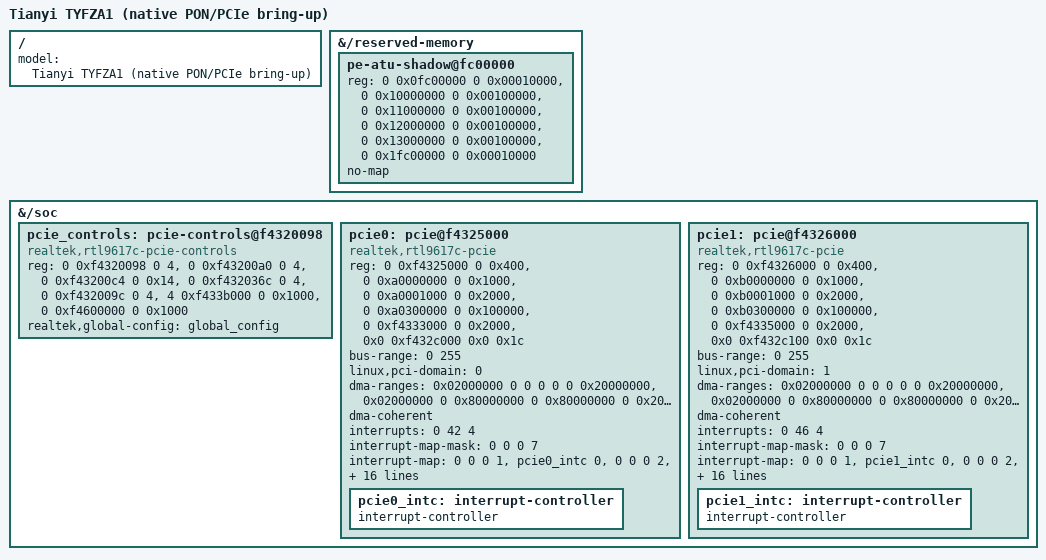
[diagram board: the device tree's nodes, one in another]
// SerDes data:stock DTB SHA256 5124f860df3bcd2e20b87d058e19b1ddfdc7a46c9d876663ba9feeff5a0f13ac.
// SPDX-License-Identifier: GPL-2.0-only
#include "rtl9617c-tyfza1-pon-status.dts"

/ { model = "Tianyi TYFZA1 (native PON/PCIe bring-up)"; };

&{/reserved-memory} {
 /* PE ATU shadows these RAM addresses with code or MMIO. Keep skb and
  * DMA allocations out of every window installed by pe_probe_core_start(). */
 pe-atu-shadow@fc00000 {
  reg = <0 0x0fc00000 0 0x00010000>,
        <0 0x10000000 0 0x00100000>,
        <0 0x11000000 0 0x00100000>,
        <0 0x12000000 0 0x00100000>,
        <0 0x13000000 0 0x00100000>,
        <0 0x1fc00000 0 0x00010000>;
  no-map;
 };
};

&{/soc} {
 pcie_controls: pcie-controls@f4320098 {
  compatible = "realtek,rtl9617c-pcie-controls";
  reg = <0 0xf4320098 0 4>, <0 0xf43200a0 0 4>,
        <0 0xf43200c4 0 0x14>, <0 0xf432036c 0 4>, <0 0xf432009c 0 4>,
        <4 0xf433b000 0 0x1000>, <0 0xf4600000 0 0x1000>;
  reg-names = "core-reset", "phy-reset", "phy-control", "power", "usb-reset",
              "sgmii-analog", "sgmii-serdes";
  realtek,global-config = <&global_config>;
  #clock-cells = <1>;
  #reset-cells = <1>;
  #phy-cells = <1>;
 };

 pcie0: pcie@f4325000 {
  compatible = "realtek,rtl9617c-pcie";
  reg = <0 0xf4325000 0 0x400>,
        <0 0xa0000000 0 0x1000>,
        <0 0xa0001000 0 0x2000>,
        <0 0xa0300000 0 0x100000>,
        <0 0xf4333000 0 0x2000>,
        <0x0 0xf432c000 0x0 0x1c>;
  reg-names = "global", "dbi", "config", "atu", "serdes", "coherent-atu";
  device_type = "pci";
  #address-cells = <3>;
  #size-cells = <2>;
  bus-range = <0 255>;
  linux,pci-domain = <0>;
  ranges = <0x81000000 0x0 0x0 0x0 0xa0003000 0x0 0x10000 0x82000000 0x0 0xa0400000 0x0 0xa0400000 0x0 0xfc00000>;
  /* RXBD bus alias reaches the SoC raw-DDR ATU window unchanged. */
  dma-ranges = <0x02000000 0 0 0 0 0 0x20000000>,
               <0x02000000 0 0x80000000 0 0x80000000 0 0x20000000>;
  dma-coherent;
  interrupts = <0 42 4>;
  interrupt-names = "wrapper";
  #interrupt-cells = <1>;
  interrupt-map-mask = <0 0 0 7>;
  interrupt-map = <0 0 0 1 &pcie0_intc 0>,
                  <0 0 0 2 &pcie0_intc 1>,
                  <0 0 0 3 &pcie0_intc 2>,
                  <0 0 0 4 &pcie0_intc 3>;
  clocks = <&pcie_controls 0>;
  resets = <&pcie_controls 0>, <&pcie_controls 2>;
  reset-names = "core", "phy";
  phys = <&pcie_controls 0>;
  phy-names = "pcie";
  reset-gpios = <&gpio0 101 GPIO_ACTIVE_LOW>; // stock bank3,pin5
  reset-delay-ms = <150>;
  num-lanes = <1>;
  realtek,controller-index = <0>;
  realtek,ddr-bytes = <0x20000000>;
  realtek,coherent-hi-addr = <4>;
  // Taurus GPL uses the B/default branch; verify cut on first board bring-up.
  realtek,serdes-profile = "B";
  serdes-cfg-dataA = <
   0x4 0xa855 0x18 0xa 0x20 0x3591 0x28 0x8670
   0x2c 0xb90d 0x34 0xf71a 0x38 0x1000 0x74 0xda1f
   0x80 0xd477 0x88 0x23 0x8c 0xb66 0x90 0x4f30
   0xa0 0xf802 0xc0 0x55 0x24 0x500c 0x24 0x520c
   0x104 0xa84a 0x118 0xa 0x120 0x3591 0x128 0x8650
   0x12c 0xb90d 0x134 0xf71a 0x138 0x1000 0x174 0xda1f
   0x180 0xd477 0x184 0x55aa 0x188 0x23 0x18c 0xb66
   0x1a0 0xf802 0x1bc 0x3900 0x1c0 0x4a 0x124 0x500c
   0x124 0x520c
  >;
  serdes-cfg-dataB = <
   0x4 0xa855 0x8 0x60c6 0x18 0x1f 0x20 0x3591
   0x28 0xf670 0x2c 0xa90d 0x34 0xf71a 0x38 0x1000
   0x74 0xda1f 0x80 0xd477 0x88 0x23 0x8c 0xb66
   0x90 0x4f30 0xa0 0xf802 0xc0 0x55 0xc8 0xf0f3
   0x24 0x500c 0x24 0x520c 0x104 0xa84a 0x108 0x60c6
   0x118 0x1f 0x120 0x3591 0x128 0xf670 0x12c 0xa90d
   0x134 0xf71a 0x138 0x1000 0x174 0xda1f 0x180 0xd479
   0x184 0x55aa 0x188 0x23 0x18c 0xb66 0x190 0x4f0c
   0x1a0 0xf802 0x1bc 0x3900 0x1c0 0x4a 0x1c8 0xf0f3
   0x124 0x500c 0x124 0x520c
  >;
  pcie0_intc: interrupt-controller {
   interrupt-controller;
   #address-cells = <0>;
   #interrupt-cells = <1>;
  };
 };

 pcie1: pcie@f4326000 {
  compatible = "realtek,rtl9617c-pcie";
  reg = <0 0xf4326000 0 0x400>,
        <0 0xb0000000 0 0x1000>,
        <0 0xb0001000 0 0x2000>,
        <0 0xb0300000 0 0x100000>,
        <0 0xf4335000 0 0x2000>,
        <0x0 0xf432c100 0x0 0x1c>;
  reg-names = "global", "dbi", "config", "atu", "serdes", "coherent-atu";
  device_type = "pci";
  #address-cells = <3>;
  #size-cells = <2>;
  bus-range = <0 255>;
  linux,pci-domain = <1>;
  ranges = <0x81000000 0x0 0x0 0x0 0xb0003000 0x0 0x10000 0x82000000 0x0 0xb0400000 0x0 0xb0400000 0x0 0xfc00000>;
  /* RXBD bus alias reaches the SoC raw-DDR ATU window unchanged. */
  dma-ranges = <0x02000000 0 0 0 0 0 0x20000000>,
               <0x02000000 0 0x80000000 0 0x80000000 0 0x20000000>;
  dma-coherent;
  interrupts = <0 46 4>;
  interrupt-names = "wrapper";
  #interrupt-cells = <1>;
  interrupt-map-mask = <0 0 0 7>;
  interrupt-map = <0 0 0 1 &pcie1_intc 0>,
                  <0 0 0 2 &pcie1_intc 1>,
                  <0 0 0 3 &pcie1_intc 2>,
                  <0 0 0 4 &pcie1_intc 3>;
  clocks = <&pcie_controls 1>;
  resets = <&pcie_controls 1>, <&pcie_controls 3>;
  reset-names = "core", "phy";
  phys = <&pcie_controls 2>;
  phy-names = "pcie";
  reset-gpios = <&gpio0 102 GPIO_ACTIVE_LOW>; // stock bank3,pin6
  reset-delay-ms = <50>;
  num-lanes = <1>;
  realtek,controller-index = <1>;
  realtek,ddr-bytes = <0x20000000>;
  realtek,coherent-hi-addr = <4>;
  // Taurus GPL uses the B/default branch; verify cut on first board bring-up.
  realtek,serdes-profile = "B";
  serdes-cfg-dataA = <
   0x4 0xa855 0x18 0xa 0x20 0x3591 0x28 0x8670
   0x2c 0xb90d 0x34 0xf71a 0x38 0x1000 0x74 0xda1f
   0x80 0xd477 0x88 0x23 0x8c 0xb66 0x90 0x4f30
   0xa0 0xf802 0xc0 0x55 0x24 0x500c 0x24 0x520c
   0x104 0xa84a 0x118 0xa 0x120 0x3591 0x128 0x8650
   0x12c 0xb90d 0x134 0xf71a 0x138 0x1000 0x174 0xda1f
   0x180 0xd477 0x184 0x55aa 0x188 0x23 0x18c 0xb66
   0x1a0 0xf802 0x1bc 0x3900 0x1c0 0x4a 0x124 0x500c
   0x124 0x520c
  >;
  serdes-cfg-dataB = <
   0x4 0xa855 0x8 0x60c6 0x18 0x1f 0x20 0x3591
   0x28 0xf670 0x2c 0xa90d 0x34 0xf71a 0x38 0x1000
   0x74 0xda1f 0x80 0xd477 0x88 0x23 0x8c 0xb66
   0x90 0x4f30 0xa0 0xf802 0xc0 0x55 0xc8 0xf0f3
   0x24 0x500c 0x24 0x520c 0x104 0xa84a 0x108 0x60c6
   0x118 0x1f 0x120 0x3591 0x128 0xf670 0x12c 0xa90d
   0x134 0xf71a 0x138 0x1000 0x174 0xda1f 0x180 0xd479
   0x184 0x55aa 0x188 0x23 0x18c 0xb66 0x190 0x4f0c
   0x1a0 0xf802 0x1bc 0x3900 0x1c0 0x4a 0x1c8 0xf0f3
   0x124 0x500c 0x124 0x520c
  >;
  pcie1_intc: interrupt-controller {
   interrupt-controller;
   #address-cells = <0>;
   #interrupt-cells = <1>;
  };
 };
};
